# fpga register map
File version: 1.0
Registers are 32-bit, read-write, reset 0x0 unless marked. A register's access mark holds for its fields unless they carry their own. Offsets are from the block's base; [hi:lo] are bit positions; <NAME> marks a mode.

## loadcell0 — hx717 dual channel 24-bit load cell adc. all three registers share one 16-byte OctoSPI prefetch line, so reading any one of them causes reads of all of them; no register here has a read side effect
Base 0x90000A00
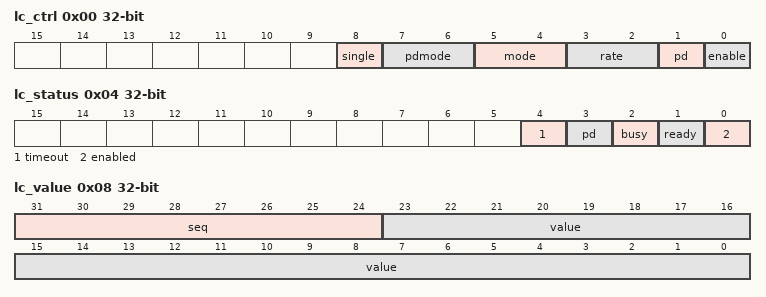
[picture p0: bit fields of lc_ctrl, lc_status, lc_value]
0x00 lc_ctrl — load cell control register
  [8] single — write 1 to take exactly one sample without setting enable. self-clearing, always reads back 0
  [7:6] pdmode — power-down depth, applied when the pd bit is honoured
    0=ADC (adc only, under 360uA. keeps the pulse count at the mode selection so channel and gain survive the sleep); 1=ADC_REG (adc and analog regulator, under 280uA. clocks 29 pulses, past the selection window, so the mode field is not applied by this conversion); 2=ALL (everything, under 1uA. clocks 30 pulses, past the selection window, so the mode field is not applied by this conversion)
  [5:4] mode — input channel and pga gain for the NEXT conversion. selected by the number of PD_SCK pulses the peripheral issues, so it applies one conversion after it is written. allow 4 conversions of settling after any change before trusting a sample
    0=A128 (channel A, gain 128, full scale +/-20mV at VREF 5V (25 pulses)); 1=B64 (channel B, gain 64, full scale +/-40mV at VREF 5V (26 pulses)); 2=A64 (channel A, gain 64, full scale +/-40mV at VREF 5V (27 pulses)); 3=B8 (channel B, gain 8, full scale +/-320mV at VREF 5V (28 pulses))
  [3:2] rate — output data rate, driven onto the S1 and S0 pins. changing this while enabled takes effect on whichever conversion the device happens to be in
    0=RATE_10HZ (10 sps, 18.2 noise-free bits); 1=RATE_20HZ (20 sps, 17.7 noise-free bits); 2=RATE_80HZ (80 sps, 16.7 noise-free bits); 3=RATE_320HZ (320 sps, 15.8 noise-free bits)
  [1] pd — request power-down. honoured only once the conversion in flight completes, so the channel and gain setup is saved. clear to wake; the device resumes with the setup it had before sleeping
  [0] enable — run conversions back to back (1 = on)
0x04 lc_status ro — load cell status register
  [4] timeout — DOUT did not go low within the watchdog interval, so no device is responding. sticky; cleared by any write to lc_ctrl
  [3] pd — the device is being held in power-down
  [2] busy — a conversion cycle is in progress. covers the wait for data as well as the pulse train, so in continuous mode this is high almost all the time and is not a useful poll target
  [1] ready — a conversion has completed since the last write to lc_ctrl, so lc_value is valid for the current configuration. cleared by writing lc_ctrl, never by a read. use the lc_value sequence number, not this bit, to detect each new sample
  [0] enabled — mirrors lc_ctrl.enable
0x08 lc_value ro — most recent conversion result plus its sequence number. reading has no side effects; a single 32-bit read gets value and sequence together so they cannot skew
  [31:24] seq — sample sequence number, incremented once per completed conversion. compare r.seq() against the last value seen using wrapping_sub, since it wraps every 256 conversions: 0.8s at 320sps, 3.2s at 80sps, 12.8s at 20sps, 25.6s at 10sps. a difference of 0 means no new conversion has completed and the value is a repeat of the one already seen; 1 is the expected case; more than 1 means that many samples were produced and never read. polling slower than the conversion period therefore reports gaps, and polling faster reports repeats - both are visible here and in neither case is lc_status.ready able to tell them apart
  [23:0] value — raw 24-bit result in two's complement, exactly as shifted off the wire. 0x00800000 is negative full scale and 0x007FFFFF positive full scale; both are also the saturation codes when the input is out of range. the generated accessor masks to 24 bits, so sign extend from bit 23 rather than from bit 31: let sample = ((r.value() as i32) << 8) >> 8; taking the raw register word instead needs ((r.0 << 8) as i32) >> 8, which drops the sequence byte in the same step. omitting the shift pair yields a value that is never negative
